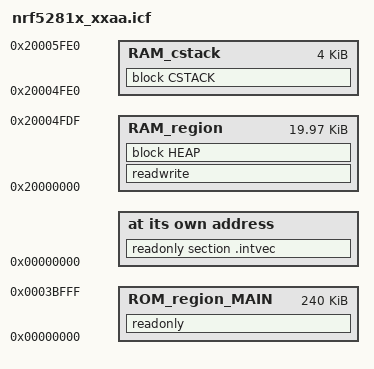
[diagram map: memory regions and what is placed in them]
/*###ICF### Section handled by ICF editor, don't touch! ****/
/*-Editor annotation file-*/
/* IcfEditorFile="$TOOLKIT_DIR$\config\linker\NordicSemi\IcfEditor\nrf52_v1.xml" */

/*-Memory Regions-*/
define symbol __MAIN_region_ROM_start__  = 0x00000000;
define symbol __MAIN_intvec_start__ = __MAIN_region_ROM_start__;
define symbol __MAIN_region_ROM_end__    = 0x3BFFF;
define symbol __ALL_region_RAM_start__ = 0x20000000;
define symbol __ALL_region_RAM_end__   = 0x20004FDF;
define symbol __ALL_stack_RAM_start__ = 0x20004FE0;
define symbol __ALL_stack_RAM_end__   = 0x20005FE0;

export symbol __MAIN_region_ROM_start__;
export symbol __MAIN_region_ROM_end__;
export symbol __ALL_stack_RAM_start__;
export symbol __ALL_stack_RAM_end__;

/*-Sizes-*/
define symbol __ALL_size_cstack__     = 0x1000;
define symbol __ALL_size_heap__       = 0x0;

/**** End of ICF editor section. ###ICF###*/

define memory mem with size = 4G;
define region ROM_region_MAIN   = mem:[from __MAIN_region_ROM_start__   to __MAIN_region_ROM_end__];
define region RAM_region   = mem:[from __ALL_region_RAM_start__   to __ALL_region_RAM_end__];
define region RAM_cstack   = mem:[from __ALL_stack_RAM_start__   to __ALL_stack_RAM_end__];

define block CSTACK    with alignment = 8, size = __ALL_size_cstack__   { };
define block HEAP      with alignment = 8, size = __ALL_size_heap__     { };

initialize by copy { readwrite };
do not initialize  { section .noinit };

keep { section .intvec };

place at address mem: __MAIN_intvec_start__ { readonly section .intvec };

place in ROM_region_MAIN   { readonly};
place in RAM_region        { readwrite,
                             block HEAP };
place in RAM_cstack        { block CSTACK };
